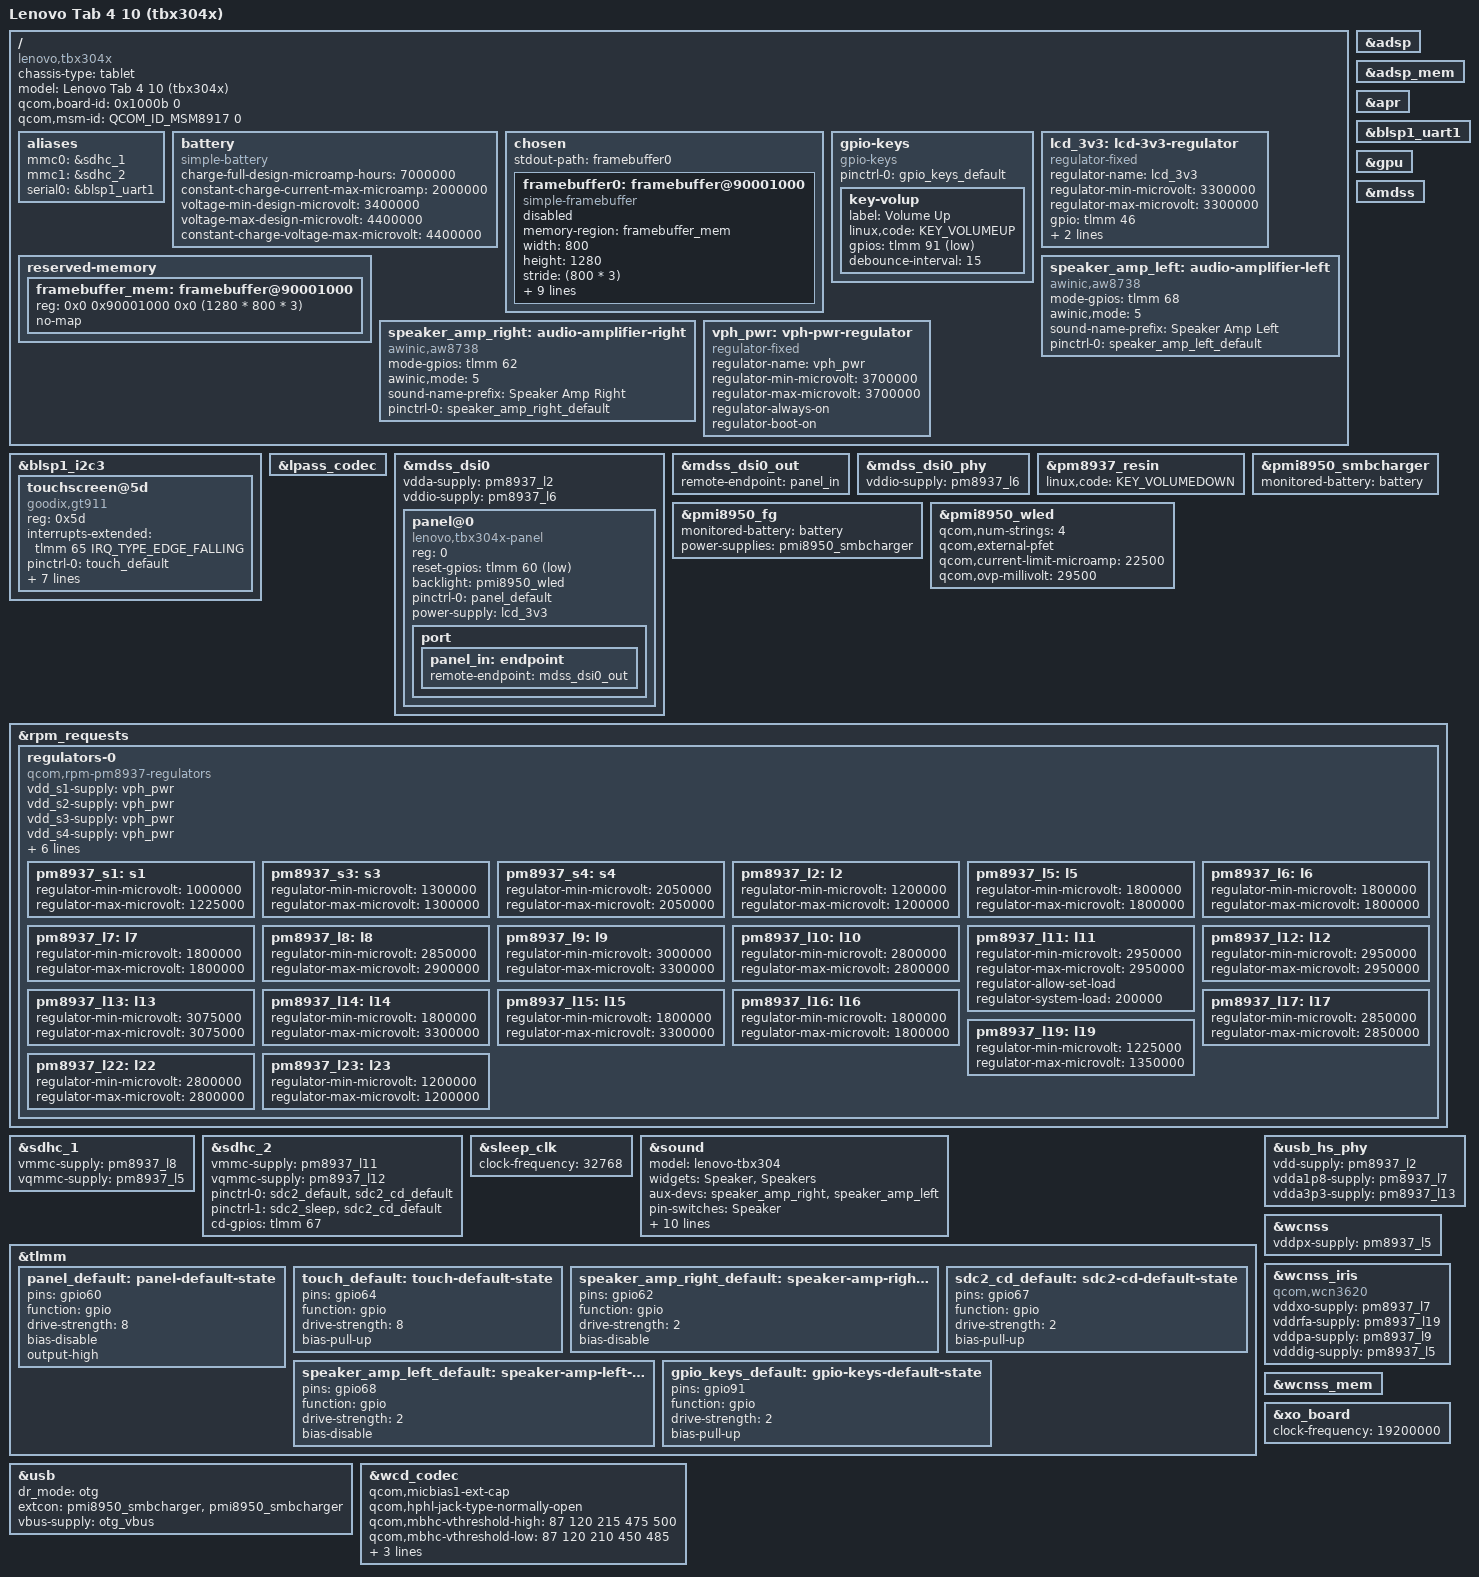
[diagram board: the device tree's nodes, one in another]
// SPDX-License-Identifier: GPL-2.0
/dts-v1/;
#include <dt-bindings/arm/qcom,ids.h>
#include <dt-bindings/gpio/gpio.h>
#include "msm8917.dtsi"
#include "pm8937.dtsi"
#include "pmi8950.dtsi"
#include "msm8937-qdsp6.dtsi"

/ {
	chassis-type = "tablet";
	compatible = "lenovo,tbx304x", "qcom,msm8917";
	model = "Lenovo Tab 4 10 (tbx304x)";
	qcom,board-id = <0x1000b 0>;
	qcom,msm-id = <QCOM_ID_MSM8917 0>;

	aliases {
		mmc0 = &sdhc_1;
		mmc1 = &sdhc_2;
		serial0 = &blsp1_uart1;
	};

	battery: battery {
		compatible = "simple-battery";

		charge-full-design-microamp-hours = <7000000>;
		constant-charge-current-max-microamp = <2000000>;

		voltage-min-design-microvolt = <3400000>;

		voltage-max-design-microvolt = <4400000>;
		constant-charge-voltage-max-microvolt = <4400000>;
	};

	chosen {
		#address-cells = <2>;
		#size-cells = <2>;
		ranges;

		stdout-path = "framebuffer0";

		framebuffer0: framebuffer@90001000 {
			compatible = "simple-framebuffer";
			memory-region = <&framebuffer_mem>;
			width = <800>;
			height = <1280>;
			stride = <(800 * 3)>;
			format = "r8g8b8";
			clocks = <&gcc GCC_MDSS_AHB_CLK>,
					 <&gcc GCC_MDSS_AXI_CLK>,
					 <&gcc GCC_MDSS_VSYNC_CLK>,
					 <&gcc GCC_MDSS_MDP_CLK>,
					 <&gcc GCC_MDSS_BYTE0_CLK>,
					 <&gcc GCC_MDSS_PCLK0_CLK>,
					 <&gcc GCC_MDSS_ESC0_CLK>;
			power-domains = <&gcc MDSS_GDSC>;
			status = "disabled";
		};
	};

	gpio-keys {
		compatible = "gpio-keys";

		pinctrl-0 = <&gpio_keys_default>;
		pinctrl-names = "default";

		key-volup {
			label = "Volume Up";
			linux,code = <KEY_VOLUMEUP>;
			gpios = <&tlmm 91 GPIO_ACTIVE_LOW>;
			debounce-interval = <15>;
		};
	};

	lcd_3v3: lcd-3v3-regulator {
		compatible = "regulator-fixed";
		regulator-name = "lcd_3v3";
		regulator-min-microvolt = <3300000>;
		regulator-max-microvolt = <3300000>;
		gpio = <&tlmm 46 GPIO_ACTIVE_HIGH>;
		enable-active-high;
		vin-supply = <&vph_pwr>;
	};

	reserved-memory {
		framebuffer_mem: framebuffer@90001000 {
			reg = <0x0 0x90001000 0x0 (1280 * 800 * 3)>;
			no-map;
		};
	};

	speaker_amp_left: audio-amplifier-left {
		compatible = "awinic,aw8738";
		mode-gpios = <&tlmm 68 GPIO_ACTIVE_HIGH>;
		awinic,mode = <5>;
		sound-name-prefix = "Speaker Amp Left";
		pinctrl-0 = <&speaker_amp_left_default>;
		pinctrl-names = "default";
	};

	speaker_amp_right: audio-amplifier-right {
		compatible = "awinic,aw8738";
		mode-gpios = <&tlmm 62 GPIO_ACTIVE_HIGH>;
		awinic,mode = <5>;
		sound-name-prefix = "Speaker Amp Right";
		pinctrl-0 = <&speaker_amp_right_default>;
		pinctrl-names = "default";
	};

	vph_pwr: vph-pwr-regulator {
		compatible = "regulator-fixed";
		regulator-name = "vph_pwr";
		regulator-min-microvolt = <3700000>;
		regulator-max-microvolt = <3700000>;
		regulator-always-on;
		regulator-boot-on;
	};
};

&adsp {
	status = "okay";
};

&adsp_mem {
	status = "okay";
};

&apr {
	status = "okay";
};

&blsp1_i2c3 {
	status = "okay";

	touchscreen@5d {
		compatible = "goodix,gt911";
		reg = <0x5d>;

		interrupts-extended = <&tlmm 65 IRQ_TYPE_EDGE_FALLING>;
		pinctrl-0 = <&touch_default>;
		pinctrl-names = "default";

		AVDD28-supply = <&pm8937_l10>;
		VDDIO-supply = <&pm8937_l5>;
		reset-gpios = <&tlmm 64 GPIO_ACTIVE_LOW>;
		touchscreen-size-x = <800>;
		touchscreen-size-y = <1280>;
		touchscreen-inverted-x;
		touchscreen-inverted-y;
	};
};

&blsp1_uart1 {
	status = "okay";
};

&gpu {
	status = "okay";
};

&lpass_codec {
	status = "okay";
};

&mdss {
	status = "okay";
};

&mdss_dsi0 {
	vdda-supply = <&pm8937_l2>;
	vddio-supply = <&pm8937_l6>;

	status = "okay";

	panel@0 {
		compatible = "lenovo,tbx304x-panel";
		reg = <0>;

		reset-gpios = <&tlmm 60 GPIO_ACTIVE_LOW>;
		backlight = <&pmi8950_wled>;

		pinctrl-0 = <&panel_default>;
		pinctrl-names = "default";

		power-supply = <&lcd_3v3>;

		port {
			panel_in: endpoint {
				remote-endpoint = <&mdss_dsi0_out>;
			};
		};
	};
};

&mdss_dsi0_out {
	remote-endpoint = <&panel_in>;
};

&mdss_dsi0_phy {
	vddio-supply = <&pm8937_l6>;
	status = "okay";
};

&pm8937_resin {
	linux,code = <KEY_VOLUMEDOWN>;

	status = "okay";
};

&pmi8950_fg {
	monitored-battery = <&battery>;
	power-supplies = <&pmi8950_smbcharger>;
	status = "okay";
};

&pmi8950_smbcharger {
	monitored-battery = <&battery>;
	status = "okay";
};

&pmi8950_wled {
	qcom,num-strings = <4>;
	qcom,external-pfet;
	qcom,current-limit-microamp = <22500>;
	qcom,ovp-millivolt = <29500>;
	status = "okay";
};

&rpm_requests {
	regulators-0 {
		compatible = "qcom,rpm-pm8937-regulators";
		vdd_s1-supply = <&vph_pwr>;
		vdd_s2-supply = <&vph_pwr>;
		vdd_s3-supply = <&vph_pwr>;
		vdd_s4-supply = <&vph_pwr>;
		vdd_l1_l19-supply = <&pm8937_s3>;
		vdd_l2_l23-supply = <&pm8937_s3>;
		vdd_l3-supply = <&pm8937_s3>;
		vdd_l4_l5_l6_l7_l16-supply = <&pm8937_s4>;
		vdd_l8_l11_l12_l17_l22-supply = <&vph_pwr>;
		vdd_l9_l10_l13_l14_l15_l18-supply = <&vph_pwr>;

		pm8937_s1: s1 {
			regulator-min-microvolt = <1000000>;
			regulator-max-microvolt = <1225000>;
		};

		pm8937_s3: s3 {
			regulator-min-microvolt = <1300000>;
			regulator-max-microvolt = <1300000>;
		};

		pm8937_s4: s4 {
			regulator-min-microvolt = <2050000>;
			regulator-max-microvolt = <2050000>;
		};

		pm8937_l2: l2 {
			regulator-min-microvolt = <1200000>;
			regulator-max-microvolt = <1200000>;
		};

		pm8937_l5: l5 {
			regulator-min-microvolt = <1800000>;
			regulator-max-microvolt = <1800000>;
		};

		pm8937_l6: l6 {
			regulator-min-microvolt = <1800000>;
			regulator-max-microvolt = <1800000>;
		};

		pm8937_l7: l7 {
			regulator-min-microvolt = <1800000>;
			regulator-max-microvolt = <1800000>;
		};

		pm8937_l8: l8 {
			regulator-min-microvolt = <2850000>;
			regulator-max-microvolt = <2900000>;
		};

		pm8937_l9: l9 {
			regulator-min-microvolt = <3000000>;
			regulator-max-microvolt = <3300000>;
		};

		pm8937_l10: l10 {
			regulator-min-microvolt = <2800000>;
			regulator-max-microvolt = <2800000>;
		};

		pm8937_l11: l11 {
			regulator-min-microvolt = <2950000>;
			regulator-max-microvolt = <2950000>;
			regulator-allow-set-load;
			regulator-system-load = <200000>;
		};

		pm8937_l12: l12 {
			regulator-min-microvolt = <2950000>;
			regulator-max-microvolt = <2950000>;
		};

		pm8937_l13: l13 {
			regulator-min-microvolt = <3075000>;
			regulator-max-microvolt = <3075000>;
		};

		pm8937_l14: l14 {
			regulator-min-microvolt = <1800000>;
			regulator-max-microvolt = <3300000>;
		};

		pm8937_l15: l15 {
			regulator-min-microvolt = <1800000>;
			regulator-max-microvolt = <3300000>;
		};

		pm8937_l16: l16 {
			regulator-min-microvolt = <1800000>;
			regulator-max-microvolt = <1800000>;
		};

		pm8937_l17: l17 {
			regulator-min-microvolt = <2850000>;
			regulator-max-microvolt = <2850000>;
		};

		pm8937_l19: l19 {
			regulator-min-microvolt = <1225000>;
			regulator-max-microvolt = <1350000>;
		};

		pm8937_l22: l22 {
			regulator-min-microvolt = <2800000>;
			regulator-max-microvolt = <2800000>;
		};

		pm8937_l23: l23 {
			regulator-min-microvolt = <1200000>;
			regulator-max-microvolt = <1200000>;
		};
	};
};

&sdhc_1 {
	vmmc-supply = <&pm8937_l8>;
	vqmmc-supply = <&pm8937_l5>;
	status = "okay";
};

&sdhc_2 {
	vmmc-supply = <&pm8937_l11>;
	vqmmc-supply = <&pm8937_l12>;
	pinctrl-0 = <&sdc2_default &sdc2_cd_default>;
	pinctrl-1 = <&sdc2_sleep &sdc2_cd_default>;
	pinctrl-names = "default", "sleep";

	cd-gpios = <&tlmm 67 GPIO_ACTIVE_HIGH>;
	status = "okay";
};

&sleep_clk {
	clock-frequency = <32768>;
};

&sound {
	model = "lenovo-tbx304";
	widgets = "Speaker", "Speakers";
	aux-devs = <&speaker_amp_right>, <&speaker_amp_left>;
	pin-switches = "Speaker";
	audio-routing = "AMIC1", "MIC BIAS Internal1",
					"AMIC2", "MIC BIAS Internal2",
					"AMIC3", "MIC BIAS External1",
					"MM_DL1", "MultiMedia1 Playback",
					"MM_DL3", "MultiMedia3 Playback",
					"MM_DL4", "MultiMedia4 Playback",
					"MultiMedia2 Capture", "MM_UL2",
					"Speaker Amp Right IN", "HPH_R",
					"Speakers", "Speaker Amp Right OUT",
					"Speaker Amp Left IN", "HPH_L",
					"Speakers", "Speaker Amp Left OUT";

	status = "okay";
};

&tlmm {
	panel_default: panel-default-state {
		pins = "gpio60";
		function = "gpio";
		drive-strength = <8>;
		bias-disable;
		output-high;
	};

	touch_default: touch-default-state {
		pins = "gpio64";
		function = "gpio";
		drive-strength = <8>;
		bias-pull-up;
	};

	speaker_amp_right_default: speaker-amp-right-default-state {
		pins = "gpio62";
		function = "gpio";
		drive-strength = <2>;
		bias-disable;
	};

	sdc2_cd_default: sdc2-cd-default-state {
		pins = "gpio67";
		function = "gpio";
		drive-strength = <2>;
		bias-pull-up;
	};

	speaker_amp_left_default: speaker-amp-left-default-state {
		pins = "gpio68";
		function = "gpio";
		drive-strength = <2>;
		bias-disable;
	};

	gpio_keys_default: gpio-keys-default-state {
		pins = "gpio91";
		function = "gpio";
		drive-strength = <2>;
		bias-pull-up;
	};
};

&usb {
	dr_mode = "otg";
	extcon = <&pmi8950_smbcharger>, <&pmi8950_smbcharger>;
	vbus-supply = <&otg_vbus>;
	status = "okay";
};

&usb_hs_phy {
	vdd-supply = <&pm8937_l2>;
	vdda1p8-supply = <&pm8937_l7>;
	vdda3p3-supply = <&pm8937_l13>;

	status = "okay";
};

&wcd_codec {
	qcom,micbias1-ext-cap;
	qcom,hphl-jack-type-normally-open;
	qcom,mbhc-vthreshold-high = <87 120 215 475 500>;
	qcom,mbhc-vthreshold-low = <87 120 210 450 485>;

	vdd-cdc-io-supply = <&pm8937_l5>;
	vdd-cdc-tx-rx-cx-supply = <&pm8937_s4>;
	vdd-micbias-supply = <&pm8937_l13>;
	status = "okay";
};

&wcnss {
	vddpx-supply = <&pm8937_l5>;
	status = "okay";
};

&wcnss_iris {
	compatible = "qcom,wcn3620";
	vddxo-supply = <&pm8937_l7>;
	vddrfa-supply = <&pm8937_l19>;
	vddpa-supply = <&pm8937_l9>;
	vdddig-supply = <&pm8937_l5>;
};

&wcnss_mem {
	status = "okay";
};

&xo_board {
	clock-frequency = <19200000>;
};
